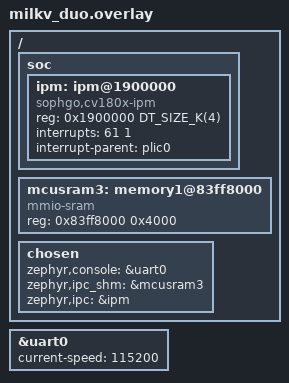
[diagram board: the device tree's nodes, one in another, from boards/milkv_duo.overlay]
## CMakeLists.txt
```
cmake_minimum_required(VERSION 3.20.0)
# Copyright (c) 2020 STMicroelectronics
#
# SPDX-License-Identifier: Apache-2.0
#

find_package(Zephyr REQUIRED HINTS $ENV{ZEPHYR_BASE})

project(openamp_tf)

# METAL_MAX_DEVICE_REGIONS is used to give the number of memory regions shared
# between processors. By default only one region is defined for the vrings
# and rpmsg buffers. The METAL_MAX_DEVICE_REGIONS has to be redefined to add a
# second region for the resource table.
zephyr_compile_definitions(METAL_MAX_DEVICE_REGIONS=2)

# These samples use local static initialization. Since Zephyr doesn't support the
# C++ ABI for thread-safe initialization of local statics and the constructors don't
# appear to require thread safety, we turn it off in the C++ compiler.
set(NO_THREADSAFE_STATICS $<TARGET_PROPERTY:compiler-cpp,no_threadsafe_statics>)
zephyr_compile_options($<$<COMPILE_LANGUAGE:CXX>:${NO_THREADSAFE_STATICS}>)

zephyr_linker_sources(SECTIONS src/resource_table.ld)

target_include_directories(app PRIVATE ${LIBMETAL_INCLUDE_DIR} ${OPENAMP_INCLUDE_DIR} ${PLATFORM_DIR})

list(APPEND CMAKE_MODULE_PATH ${ZEPHYR_BASE}/modules/nanopb)
include(nanopb)
zephyr_nanopb_sources(app src/message.proto)

file(GLOB app_sources src/*)
target_sources(app PRIVATE ${app_sources})
```

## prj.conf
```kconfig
# GENERAL ----------------
CONFIG_CONSOLE=y
CONFIG_UART_CONSOLE=y
CONFIG_STDOUT_CONSOLE=y
CONFIG_NANOPB=y
# CONFIG_TIMING_FUNCTIONS=y

# CONFIG_THREAD_ANALYZER=y
# CONFIG_THREAD_ANALYZER_USE_PRINTK=y
# CONFIG_THREAD_ANALYZER_AUTO=y
# CONFIG_THREAD_ANALYZER_AUTO_INTERVAL=5
# CONFIG_THREAD_NAME=y
# CONFIG_THREAD_RUNTIME_STATS=y

# OPENAMP ----------------
CONFIG_IPM=y
CONFIG_SOPHGO_CV180X_IPM=y
CONFIG_MAIN_STACK_SIZE=1024
CONFIG_HEAP_MEM_POOL_SIZE=1024
CONFIG_OPENAMP=y
CONFIG_OPENAMP_RSC_TABLE=y
CONFIG_OPENAMP_MASTER=n

# depends on size of RPMSG_BUFFER_SIZE declared in linux (driver/rpmsg/virtio_rpmsg_bus.c) and the reserved memory in devicetree
# ex: if reserved memory of each vring is 8kB and RPMSG_BUFFER_SIZE is 4kB, then CONFIG_OPENAMP_RSC_TABLE_NUM_RPMSG_BUFF=2
# RPMSG_BUFFER_SIZE = 4096 -> 	CONFIG_OPENAMP_RSC_TABLE_NUM_RPMSG_BUFF=2  	(max)
# RPMSG_BUFFER_SIZE = 2048 ->  	CONFIG_OPENAMP_RSC_TABLE_NUM_RPMSG_BUFF=4 	(max)
# RPMSG_BUFFER_SIZE = 512 ->  	CONFIG_OPENAMP_RSC_TABLE_NUM_RPMSG_BUFF=15 	(max)
CONFIG_OPENAMP_RSC_TABLE_NUM_RPMSG_BUFF=4

# TENSORFLOW LITE MICRO ----------------
CONFIG_CPP=y
CONFIG_STD_CPP17=y
CONFIG_TENSORFLOW_LITE_MICRO=y
CONFIG_MAIN_STACK_SIZE=2048
CONFIG_REQUIRES_FLOAT_PRINTF=y
```

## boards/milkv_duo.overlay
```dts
/ {
	#address-cells = <1>;
	#size-cells = <1>;
	
	soc {
		ipm:ipm@1900000 {
			compatible = "sophgo,cv180x-ipm";
			reg = <0x1900000 DT_SIZE_K(4)>;
			interrupts = <61 1>;
			interrupt-parent = <&plic0>;
			status = "disabled";
		};
	};

	// location of vdev0buffer in linux dts
	mcusram3: memory1@83ff8000 {
		compatible = "mmio-sram";
		reg = <0x83ff8000 0x4000>;
	};

	chosen {
		zephyr,console = &uart0;
		zephyr,ipc_shm = &mcusram3;
		zephyr,ipc = &ipm;
    };
};

&uart0 {
	status = "okay";
	current-speed = <115200>;
};

&ipm {
	status = "okay";
};
```

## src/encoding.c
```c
#include "encoding.h"
#include "src/message.pb.h"
#include <zephyr/kernel.h>

Board_Mark get_mark(char mark)
{
	switch (mark) {
	case 'X':
		return Board_Mark_MARK_X;
	case 'O':
		return Board_Mark_MARK_O;
	default:
		return Board_Mark_MARK_EMPTY;
	}
}

char get_mark_char(Board_Mark mark)
{
	switch (mark) {
	case Board_Mark_MARK_X:
		return 'X';
	case Board_Mark_MARK_O:
		return 'O';
	default:
		return ' ';
	}
}

int encode_board(char board[3][3], uint8_t *buffer, size_t buffer_size)
{
	Board message = Board_init_zero;

	for (int i = 0; i < 3; i++) {
		for (int j = 0; j < 3; j++) {
			message.rows[i].marks[j] = get_mark(board[i][j]);
		}
		message.rows[i].marks_count = 3;
	}
	message.rows_count = 3;

	// create stream that will write to our buffer
	pb_ostream_t stream = pb_ostream_from_buffer(buffer, buffer_size);

	// Encode the message
	bool status = pb_encode(&stream, Board_fields, &message);
	size_t message_length = stream.bytes_written;

	if (!status) {
		printk("Encoding failed: %s\n", PB_GET_ERROR(&stream));
		return ERROR;
	}

	return message_length;
}

int decode_board(char board[3][3], uint8_t *buffer, size_t message_length)
{
	/* Initialize the message structure to zero */
	Board message = Board_init_zero;

	/* Create a stream that reads from the buffer */
	pb_istream_t stream = pb_istream_from_buffer(buffer, message_length);

	/* Decode the message */
	int status = pb_decode(&stream, Board_fields, &message);

	/* Check for decoding errors */
	if (!status) {
		printk("Decoding failed: %s\n", PB_GET_ERROR(&stream));
		return ERROR;
	}

	for (int i = 0; i < 3; i++) {
		for (int j = 0; j < 3; j++) {
			board[i][j] = get_mark_char(message.rows[i].marks[j]);
		}
	}

	return SUCCESS;
}
```

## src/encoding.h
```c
#ifndef ENCODING_H
#define ENCODING_H

#include <pb_encode.h>
#include <pb_decode.h>

#define ERROR   -1
#define SUCCESS 0

int encode_board(char board[3][3], uint8_t *buffer, size_t buffer_size);
int decode_board(char board[3][3], uint8_t *buffer, size_t buffer_size);

#endif // !ENCODING_H
```

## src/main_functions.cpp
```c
/*
 * Copyright 2020 The TensorFlow Authors. All Rights Reserved.
 *
 * Licensed under the Apache License, Version 2.0 (the "License");
 * you may not use this file except in compliance with the License.
 * You may obtain a copy of the License at
 *
 *     http://www.apache.org/licenses/LICENSE-2.0
 *
 * Unless required by applicable law or agreed to in writing, software
 * distributed under the License is distributed on an "AS IS" BASIS,
 * WITHOUT WARRANTIES OR CONDITIONS OF ANY KIND, either express or implied.
 * See the License for the specific language governing permissions and
 * limitations under the License.
 */

#include "main_functions.h"

#include <tensorflow/lite/micro/micro_mutable_op_resolver.h>
#include "constants.h"
#include "model.hpp"
#include "output_handler.hpp"
#include <tensorflow/lite/micro/micro_log.h>
#include <tensorflow/lite/micro/micro_interpreter.h>
#include <tensorflow/lite/micro/system_setup.h>
#include <tensorflow/lite/schema/schema_generated.h>

/* Globals, used for compatibility with Arduino-style sketches. */
namespace
{
const tflite::Model *model = nullptr;
tflite::MicroInterpreter *interpreter = nullptr;
TfLiteTensor *input = nullptr;
TfLiteTensor *output = nullptr;
int inference_count = 0;

constexpr int kTensorArenaSize = 2000;
uint8_t tensor_arena[kTensorArenaSize];
} /* namespace */

/* The name of this function is important for Arduino compatibility. */
void setup(void)
{
	/* Map the model into a usable data structure. This doesn't involve any
	 * copying or parsing, it's a very lightweight operation.
	 */
	model = tflite::GetModel(g_model);
	if (model->version() != TFLITE_SCHEMA_VERSION) {
		MicroPrintf("Model provided is schema version %d not equal "
			    "to supported version %d.",
			    model->version(), TFLITE_SCHEMA_VERSION);
		return;
	}

	/* This pulls in the operation implementations we need.
	 * NOLINTNEXTLINE(runtime-global-variables)
	 */
	static tflite::MicroMutableOpResolver<1> resolver;
	resolver.AddFullyConnected();

	/* Build an interpreter to run the model with. */
	static tflite::MicroInterpreter static_interpreter(model, resolver, tensor_arena,
							   kTensorArenaSize);
	interpreter = &static_interpreter;

	/* Allocate memory from the tensor_arena for the model's tensors. */
	TfLiteStatus allocate_status = interpreter->AllocateTensors();
	if (allocate_status != kTfLiteOk) {
		MicroPrintf("AllocateTensors() failed");
		return;
	}

	/* Obtain pointers to the model's input and output tensors. */
	input = interpreter->input(0);
	output = interpreter->output(0);

	/* Keep track of how many inferences we have performed. */
	inference_count = 0;
}

/* The name of this function is important for Arduino compatibility. */
void loop(void)
{
	/* Calculate an x value to feed into the model. We compare the current
	 * inference_count to the number of inferences per cycle to determine
	 * our position within the range of possible x values the model was
	 * trained on, and use this to calculate a value.
	 */
	float position =
		static_cast<float>(inference_count) / static_cast<float>(kInferencesPerCycle);
	float x = position * kXrange;

	float y = infer(x);

	/* Output the results. A custom HandleOutput function can be implemented
	 * for each supported hardware target.
	 */
	HandleOutput(x, y);

	/* Increment the inference_counter, and reset it if we have reached
	 * the total number per cycle
	 */
	inference_count += 1;
	if (inference_count >= kInferencesPerCycle) {
		inference_count = 0;
	}
}

float infer(float x)
{
	/* Quantize the input from floating-point to integer */
	int8_t x_quantized = x / input->params.scale + input->params.zero_point;
	/* Place the quantized input in the model's input tensor */
	input->data.int8[0] = x_quantized;

	/* Run inference, and report any error */
	TfLiteStatus invoke_status = interpreter->Invoke();
	if (invoke_status != kTfLiteOk) {
		MicroPrintf("Invoke failed on x: %f\n", static_cast<double>(x));
		return -1;
	}

	/* Obtain the quantized output from model's output tensor */
	int8_t y_quantized = output->data.int8[0];
	/* Dequantize the output from integer to floating-point */
	float y = (y_quantized - output->params.zero_point) * output->params.scale;

	return y;
}
```

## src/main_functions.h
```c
/*
 * Copyright 2020 The TensorFlow Authors. All Rights Reserved.
 *
 * Licensed under the Apache License, Version 2.0 (the "License");
 * you may not use this file except in compliance with the License.
 * You may obtain a copy of the License at
 *
 *     http://www.apache.org/licenses/LICENSE-2.0
 *
 * Unless required by applicable law or agreed to in writing, software
 * distributed under the License is distributed on an "AS IS" BASIS,
 * WITHOUT WARRANTIES OR CONDITIONS OF ANY KIND, either express or implied.
 * See the License for the specific language governing permissions and
 * limitations under the License.
 */

#ifndef TENSORFLOW_LITE_MICRO_EXAMPLES_HELLO_WORLD_MAIN_FUNCTIONS_H_
#define TENSORFLOW_LITE_MICRO_EXAMPLES_HELLO_WORLD_MAIN_FUNCTIONS_H_

/* Expose a C friendly interface for main functions. */
#ifdef __cplusplus
extern "C" {
#endif

/* Initializes all data needed for the example. The name is important, and needs
 * to be setup() for Arduino compatibility.
 */
void setup(void);

/* Runs one iteration of data gathering and inference. This should be called
 * repeatedly from the application code. The name needs to be loop() for Arduino
 * compatibility.
 */
void loop(void);

/* Run inference on the data provided.
 */
float infer(float x);

#ifdef __cplusplus
}
#endif

#endif /* TENSORFLOW_LITE_MICRO_EXAMPLES_HELLO_WORLD_MAIN_FUNCTIONS_H_ */
```

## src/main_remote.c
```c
/*
 * Copyright (c) 2020, STMICROELECTRONICS
 *
 * SPDX-License-Identifier: Apache-2.0
 */

#include "openamp/rpmsg.h"
#include "main_functions.h"
#include "tictactoe.h"
#include "encoding.h"

#include <zephyr/sys/printk.h>
#include <zephyr/kernel.h>
#include <zephyr/device.h>
#include <stdint.h>
#include <string.h>
#include <stdio.h>
#include <stdlib.h>
#include <string.h>

#include <zephyr/drivers/ipm.h>

#include <openamp/open_amp.h>
#include <metal/device.h>
#include <resource_table.h>

#include <zephyr/logging/log.h>

LOG_MODULE_REGISTER(openamp_rsc_table, LOG_LEVEL_INF);

#define SHM_DEVICE_NAME "shm"

#define MBOX_TX_CHAN 2
#define MBOX_RX_CHAN 3

#if !DT_HAS_CHOSEN(zephyr_ipc_shm)
#error "Sample requires definition of shared memory for rpmsg"
#endif

/* Constants derived from device tree */
#define SHM_NODE       DT_CHOSEN(zephyr_ipc_shm)
#define SHM_START_ADDR DT_REG_ADDR(SHM_NODE)
#define SHM_SIZE       DT_REG_SIZE(SHM_NODE)

static const struct device *const ipm_handle = DEVICE_DT_GET(DT_CHOSEN(zephyr_ipc));

static metal_phys_addr_t shm_physmap = SHM_START_ADDR;

struct metal_device shm_device = {.name = SHM_DEVICE_NAME,
				  .num_regions = 2,
				  .regions =
					  {
						  {.virt = NULL}, /* shared memory */
						  {.virt = NULL}, /* rsc_table memory */
					  },
				  .node = {NULL},
				  .irq_num = 0,
				  .irq_info = NULL};

struct rpmsg_rcv_msg {
	void *data;
	size_t len;
};

static struct metal_io_region *shm_io;
static struct rpmsg_virtio_shm_pool shpool;

static struct metal_io_region *rsc_io;
static struct rpmsg_virtio_device rvdev;

static void *rsc_table;
static struct rpmsg_device *rpdev;

static K_SEM_DEFINE(data_sem, 0, 1);

// app specific variables
#define APP_RPMSG_TASK_STACK_SIZE (2048)
static K_SEM_DEFINE(data_app_sem, 0, 1);
K_THREAD_STACK_DEFINE(thread_netlink_stack, APP_RPMSG_TASK_STACK_SIZE);

#define APP_TTT_TASK_STACK_SIZE (4096)
static K_SEM_DEFINE(data_ttt_sem, 0, 1);
K_THREAD_STACK_DEFINE(thread_ttt_stack, APP_TTT_TASK_STACK_SIZE);

#define APP_MNG_TASK_STACK_SIZE (1024)
K_THREAD_STACK_DEFINE(thread_mng_stack, APP_MNG_TASK_STACK_SIZE);

static void platform_ipm_callback(const struct device *dev, void *context, uint32_t id,
				  volatile void *data)
{
	LOG_DBG("msg received from mailbox chan %d\n", id);
	if (id == MBOX_RX_CHAN) {
		k_sem_give(&data_sem);
	}
}

static int rpmsg_recv_ttt_callback(struct rpmsg_endpoint *ept, void *data, size_t len, uint32_t src,
				   void *priv)
{
	struct rpmsg_rcv_msg *msg = priv;

	rpmsg_hold_rx_buffer(ept, data);
	msg->data = data;
	msg->len = len;
	k_sem_give(&data_ttt_sem);

	return RPMSG_SUCCESS;
}

static int rpmsg_recv_netlink_callback(struct rpmsg_endpoint *ept, void *data, size_t len,
				       uint32_t src, void *priv)
{
	struct rpmsg_rcv_msg *msg = priv;

	rpmsg_hold_rx_buffer(ept, data);
	msg->data = data;
	msg->len = len;
	k_sem_give(&data_app_sem);

	return RPMSG_SUCCESS;
}

static void receive_message(unsigned char **msg, unsigned int *len)
{
	int status = k_sem_take(&data_sem, K_FOREVER);

	if (status == 0) {
		rproc_virtio_notified(rvdev.vdev, VRING1_ID);
	}
}

static void new_service_cb(struct rpmsg_device *rdev, const char *name, uint32_t src)
{
	LOG_ERR("%s: unexpected ns service receive for name %s\n", __func__, name);
}

int mailbox_notify(void *priv, uint32_t id)
{
	ARG_UNUSED(priv);

	if (id == 0) {
		LOG_DBG("sending kick to mailbox chan %d\n", MBOX_TX_CHAN);
		ipm_send(ipm_handle, 0, MBOX_TX_CHAN, NULL, 0);
	}

	return 0;
}

unsigned long phys_to_offset(struct metal_io_region *io, metal_phys_addr_t phys)
{
	return (unsigned long)phys - (unsigned long)io->virt;
}

int platform_init(void)
{
	void *rsc_tab_addr;
	int rsc_size;
	struct metal_device *device;
	struct metal_init_params metal_params = METAL_INIT_DEFAULTS;
	int status;

	const struct metal_io_ops nops = {
		.phys_to_offset = phys_to_offset,
	};

	status = metal_init(&metal_params);
	if (status) {
		LOG_DBG("metal_init: failed: %d\n", status);
		return -1;
	}

	status = metal_register_generic_device(&shm_device);
	if (status) {
		LOG_DBG("Couldn't register shared memory: %d\n", status);
		return -1;
	}

	status = metal_device_open("generic", SHM_DEVICE_NAME, &device);
	if (status) {
		LOG_DBG("metal_device_open failed: %d\n", status);
		return -1;
	}

	/* declare shared memory region */
	metal_io_init(&device->regions[0], (void *)SHM_START_ADDR, &shm_physmap, SHM_SIZE, -1, 0,
		      &nops);

	shm_io = metal_device_io_region(device, 0);
	if (!shm_io) {
		LOG_DBG("Failed to get shm_io region\n");
		return -1;
	}

	/* declare resource table region */
	rsc_table_get((struct fw_resource_table **)&rsc_tab_addr, &rsc_size);
	rsc_table = (struct st_resource_table *)rsc_tab_addr;

	metal_io_init(&device->regions[1], rsc_table, (metal_phys_addr_t *)rsc_table, rsc_size, -1,
		      0, NULL);

	rsc_io = metal_device_io_region(device, 1);
	if (!rsc_io) {
		LOG_DBG("Failed to get rsc_io region\n");
		return -1;
	}

	/* setup IPM */
	if (!device_is_ready(ipm_handle)) {
		LOG_DBG("IPM device is not ready\n");
		return -1;
	}

	ipm_register_callback(ipm_handle, platform_ipm_callback, NULL);

	status = ipm_set_enabled(ipm_handle, 1);
	if (status) {
		LOG_DBG("ipm_set_enabled failed\n");
		return -1;
	}

	return 0;
}

static void cleanup_system(void)
{
	ipm_set_enabled(ipm_handle, 0);
	rpmsg_deinit_vdev(&rvdev);
	metal_finish();
}

struct rpmsg_device *platform_create_rpmsg_vdev(unsigned int vdev_index, unsigned int role,
						void (*rst_cb)(struct virtio_device *vdev),
						rpmsg_ns_bind_cb ns_cb)
{
	struct fw_rsc_vdev_vring *vring_rsc;
	struct virtio_device *vdev;
	int ret;

	vdev = rproc_virtio_create_vdev(VIRTIO_DEV_DEVICE, VDEV_ID, rsc_table_to_vdev(rsc_table),
					rsc_io, NULL, mailbox_notify, NULL);

	if (!vdev) {
		LOG_DBG("failed to create vdev\r\n");
		return NULL;
	}

	/* wait master rpmsg init completion */
	rproc_virtio_wait_remote_ready(vdev);

	vring_rsc = rsc_table_get_vring0(rsc_table);
	ret = rproc_virtio_init_vring(vdev, 0, vring_rsc->notifyid,
				      (void *)(uintptr_t)(vring_rsc->da), rsc_io, vring_rsc->num,
				      vring_rsc->align);
	if (ret) {
		LOG_DBG("failed to init vring 0\r\n");
		goto failed;
	}

	vring_rsc = rsc_table_get_vring1(rsc_table);
	ret = rproc_virtio_init_vring(vdev, 1, vring_rsc->notifyid,
				      (void *)(uintptr_t)vring_rsc->da, rsc_io, vring_rsc->num,
				      vring_rsc->align);
	if (ret) {
		LOG_DBG("failed to init vring 1\r\n");
		goto failed;
	}

	rpmsg_virtio_init_shm_pool(&shpool, NULL, SHM_SIZE);
	ret = rpmsg_init_vdev(&rvdev, vdev, ns_cb, shm_io, &shpool);

	if (ret) {
		LOG_DBG("failed rpmsg_init_vdev\r\n");
		goto failed;
	}

	return rpmsg_virtio_get_rpmsg_device(&rvdev);

failed:
	rproc_virtio_remove_vdev(vdev);

	return NULL;
}

void ttt(void *arg1, void *arg2, void *arg3)
{
	ARG_UNUSED(arg1);
	ARG_UNUSED(arg2);
	ARG_UNUSED(arg3);

	static struct rpmsg_endpoint ept;
	static struct rpmsg_rcv_msg msg;

	int ret = 0;

	k_sem_take(&data_ttt_sem, K_FOREVER);

	printk("\r\nOpenAMP[remote] rpmsg-ttt tictactoe player started\r\n");

	ept.priv = &msg;
	ret = rpmsg_create_ept(&ept, rpdev, "rpmsg-ttt", RPMSG_ADDR_ANY, RPMSG_ADDR_ANY,
			       rpmsg_recv_ttt_callback, NULL);

	char board[3][3] = {{' '}, {' '}, {' '}};

	while (ept.addr != RPMSG_ADDR_ANY) {
		k_sem_take(&data_ttt_sem, K_FOREVER);

		ret = decode_board(board, (uint8_t *)msg.data, msg.len);
		if (ret < 0) {
			printk("Decoding failed\n");
			continue;
		}

		// determine the best move
		struct action best_move;
		minimax(board, &best_move);

		if (best_move.row == -1) {
			// game over
			rpmsg_send(&ept, msg.data, msg.len);
			continue;
		}

		// make move
		board[best_move.row][best_move.col] = player(board);

		draw(board);

		// encode board
		ret = encode_board(board, (uint8_t *)msg.data, msg.len);

		if (ret < 0) {
			printk("Encoding failed\n");
			continue;
		}

		rpmsg_send(&ept, msg.data, ret);

		msg.len = 0;
		rpmsg_release_rx_buffer(&ept, msg.data);
	}

	rpmsg_destroy_ept(&ept);
}

void app(void *arg1, void *arg2, void *arg3)
{
	ARG_UNUSED(arg1);
	ARG_UNUSED(arg2);
	ARG_UNUSED(arg3);

	static struct rpmsg_endpoint ept;
	static struct rpmsg_rcv_msg msg;

	int ret = 0;

	// initialize tensorflow
	setup();

	k_sem_take(&data_app_sem, K_FOREVER);

	printk("\r\nOpenAMP[remote] rpmsg-tflite tensorflow sine predictor started\r\n");

	ept.priv = &msg;
	ret = rpmsg_create_ept(&ept, rpdev, "rpmsg-tflite", RPMSG_ADDR_ANY, RPMSG_ADDR_ANY,
			       rpmsg_recv_netlink_callback, NULL);

	while (ept.addr != RPMSG_ADDR_ANY) {
		k_sem_take(&data_app_sem, K_FOREVER);

		if (msg.len) {
			// process app data
			float *input = (float *)msg.data;
			for (int i = 0; i < msg.len / sizeof(float); i++) {
				float x = input[i];
				float y = infer(x);
				input[i] = y;
			}

			rpmsg_send(&ept, msg.data, msg.len);
		}

		msg.len = 0;
		rpmsg_release_rx_buffer(&ept, msg.data);
	}

	rpmsg_destroy_ept(&ept);
}

void rpmsg_mng_task(void *arg1, void *arg2, void *arg3)
{
	ARG_UNUSED(arg1);
	ARG_UNUSED(arg2);
	ARG_UNUSED(arg3);

	unsigned char *msg;
	unsigned int len;
	int ret = 0;

	printk("\r\nOpenAMP[remote] application started\r\n");

	/* Initialize platform */
	ret = platform_init();
	if (ret) {
		LOG_ERR("Failed to initialize platform\n");
		ret = -1;
		goto task_end;
	}

	// Create rpmsg vdev - Only one shared channel, different services are provided through
	// different endpoints
	rpdev = platform_create_rpmsg_vdev(0, VIRTIO_DEV_DEVICE, NULL, new_service_cb);
	if (!rpdev) {
		LOG_ERR("Failed to create rpmsg virtio device\n");
		ret = -1;
		goto task_end;
	}

	printk("RPMSG tx buffer size: %d\n", rpmsg_virtio_get_tx_buffer_size(rpdev));

	/* start the rpmsg clients */
	k_sem_give(&data_app_sem);
	k_sem_give(&data_ttt_sem);

	while (1) {
		receive_message(&msg, &len);
	}

task_end:
	cleanup_system();

	printk("OpenAMP demo ended\n");
}

int main(void)
{
	printk("Starting application threads!\n");

	static struct k_thread thread_app_data;
	static struct k_thread thread_mng_data;
	static struct k_thread thread_ttt_data;

	k_tid_t mng =
		k_thread_create(&thread_mng_data, thread_mng_stack, APP_MNG_TASK_STACK_SIZE,
				rpmsg_mng_task, NULL, NULL, NULL, K_PRIO_COOP(8), 0, K_NO_WAIT);

	k_tid_t app_thread =
		k_thread_create(&thread_app_data, thread_netlink_stack, APP_RPMSG_TASK_STACK_SIZE,
				app, NULL, NULL, NULL, K_PRIO_COOP(7), 0, K_NO_WAIT);

	k_tid_t ttt_thread =
		k_thread_create(&thread_ttt_data, thread_ttt_stack, APP_TTT_TASK_STACK_SIZE, ttt,
				NULL, NULL, NULL, K_PRIO_COOP(7), 0, K_NO_WAIT);

	k_thread_name_set(mng, "manager");
	k_thread_name_set(app_thread, "sine_predictor");
	k_thread_name_set(ttt_thread, "ttt");

	return 0;
}
```

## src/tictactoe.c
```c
#include "tictactoe.h"
#include <stdio.h>
#include <limits.h>

#define X     'X'
#define O     'O'
#define EMPTY ' '

/**
 * @brief Initialize the board to the initial state
 */
void initial_state(char board[3][3])
{
	for (int i = 0; i < 3; i++) {
		for (int j = 0; j < 3; j++) {
			board[i][j] = EMPTY;
		}
	}
}

/**
 * @brief Determine the current player
 * @param board The current board
 * @return char The current player
 */
char player(char board[3][3])
{
	int x_count = 0, o_count = 0;
	for (int i = 0; i < 3; i++) {
		for (int j = 0; j < 3; j++) {
			if (board[i][j] == X) {
				x_count++;
			} else if (board[i][j] == O) {
				o_count++;
			}
		}
	}
	return (x_count > o_count) ? O : X;
}

/**
 * @brief Determine the available actions
 * @param board The current board
 * @param action_list The list of available actions
 * @return int The number of available actions
 */
int actions(char board[3][3], struct action action_list[9])
{
	int count = 0;
	for (int i = 0; i < 3; i++) {
		for (int j = 0; j < 3; j++) {
			if (board[i][j] == EMPTY) {
				action_list[count].row = i;
				action_list[count].col = j;
				count++;
			}
		}
	}
	return count;
}

/**
 * @brief Apply a move and return a new board
 * @param new_board The new board
 * @param board The current board
 * @param action The action to apply
 */
void result(char new_board[3][3], char board[3][3], struct action action)
{
	for (int k = 0; k < 3; k++) {
		for (int l = 0; l < 3; l++) {
			new_board[k][l] = board[k][l];
		}
	}
	new_board[action.row][action.col] = player(board);
}

/**
 * @brief Check for a winner
 * @param board The current board
 * @return char The winner
 */
char winner(char board[3][3])
{
	for (int i = 0; i < 3; i++) {
		if (board[i][0] == board[i][1] && board[i][0] == board[i][2] &&
		    board[i][0] != EMPTY) {
			return board[i][0];
		}
		if (board[0][i] == board[1][i] && board[0][i] == board[2][i] &&
		    board[0][i] != EMPTY) {
			return board[0][i];
		}
	}
	if (board[0][0] == board[1][1] && board[0][0] == board[2][2] && board[0][0] != EMPTY) {
		return board[0][0];
	}
	if (board[0][2] == board[1][1] && board[0][2] == board[2][0] && board[0][2] != EMPTY) {
		return board[0][2];
	}
	return EMPTY;
}

/**
 * @brief Check if the game is over
 * @param board The current board
 * @return int 1 if the game is over, 0 otherwise
 */
int terminal(char board[3][3])
{
	if (winner(board) != EMPTY) {
		return 1;
	}
	for (int i = 0; i < 3; i++) {
		for (int j = 0; j < 3; j++) {
			if (board[i][j] == EMPTY) {
				return 0;
			}
		}
	}
	return 1;
}

/**
 * @brief Calculate the utility of the board
 * @param board The current board
 * @return int The utility of the board
 */
int utility(char board[3][3])
{
	char win = winner(board);
	if (win == X) {
		return 1;
	} else if (win == O) {
		return -1;
	} else {
		return 0;
	}
}

// Maximize function
int Max_Value(char board[3][3]);

// Minimize function
int Min_Value(char board[3][3])
{
	if (terminal(board)) {
		return utility(board);
	}

	int v = INT_MAX;
	struct action action_list[9];
	int actions_count = actions(board, action_list);

	for (int i = 0; i < actions_count; i++) {
		char new_board[3][3];
		result(new_board, board, action_list[i]);
		int max_val = Max_Value(new_board);
		if (max_val < v) {
			v = max_val;
		}
	}
	return v;
}

// Maximize function
int Max_Value(char board[3][3])
{
	if (terminal(board)) {
		return utility(board);
	}

	int v = INT_MIN;
	struct action action_list[9];
	int actions_count = actions(board, action_list);

	for (int i = 0; i < actions_count; i++) {
		char new_board[3][3];
		result(new_board, board, action_list[i]);
		int min_val = Min_Value(new_board);
		if (min_val > v) {
			v = min_val;
		}
	}
	return v;
}

/**
 * @brief Minimax algorithm
 * @param board The current board
 * @param best_move The best move
 */
void minimax(char board[3][3], struct action *best_move)
{
	if (terminal(board)) {
		best_move->row = -1;
		best_move->col = -1;
		return;
	}

	int best_val;
	if (player(board) == X) {
		best_val = INT_MIN;
	} else {
		best_val = INT_MAX;
	}

	struct action action_list[9];
	int actions_count = actions(board, action_list);

	for (int i = 0; i < actions_count; i++) {
		char new_board[3][3];
		result(new_board, board, action_list[i]);

		int current_val;
		if (player(board) == X) {
			current_val = Min_Value(new_board);
			if (current_val > best_val) {
				best_val = current_val;
				best_move->row = action_list[i].row;
				best_move->col = action_list[i].col;
			}
		} else {
			current_val = Max_Value(new_board);
			if (current_val < best_val) {
				best_val = current_val;
				best_move->row = action_list[i].row;
				best_move->col = action_list[i].col;
			}
		}
	}
}

/**
 * @brief Draw the board
 * @param board The current board
 */
void draw(char board[3][3])
{
	// printf("\033[H\033[J"); // clear screen
	printf("\t0\t1\t2\n\n");
	for (int i = 0; i < 3; i++) {
		printf("%d", i);
		for (int j = 0; j < 3; j++) {
			printf("\t%c", board[i][j]);
		}
		printf("\n\n");
	}
}

char BOARD[3][3];
int user_turn;
char play_marker;

static void setup()
{
	initial_state(BOARD);
	printf("Do you want to play first? (1 for yes, 0 for no): ");
	scanf("%d", &user_turn);
	user_turn = user_turn ? 1 : 0;
	play_marker = user_turn ? X : O;
}

static void loop()
{
	struct action best_move;
	struct action user_move;

	while (!terminal(BOARD)) {
		draw(BOARD);
		printf("You are %c\n", play_marker);

		if (user_turn) {
			printf("Enter your move (row column): ");
			while (1) {
				scanf("%d %d", &user_move.row, &user_move.col);
				if (user_move.row < 0 || user_move.row > 2 || user_move.col < 0 ||
				    user_move.col > 2) {
					printf("Invalid move, try again: ");
					continue;
				}
				if (BOARD[user_move.row][user_move.col] == EMPTY) {
					break;
				}
				printf("Invalid move, try again: ");
			}
			BOARD[user_move.row][user_move.col] = player(BOARD);
			user_turn = 0;
		} else {
			minimax(BOARD, &best_move);
			if (best_move.row == -1) {
				break;
			}
			BOARD[best_move.row][best_move.col] = player(BOARD);
			user_turn = 1;
		}
	}

	draw(BOARD);
	printf("You are %c\n", play_marker);
	if (winner(BOARD) == X) {
		printf("X wins!\n");
	} else if (winner(BOARD) == O) {
		printf("O wins!\n");
	} else {
		printf("It's a draw!\n");
	}
}
```

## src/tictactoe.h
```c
#ifndef TICTACTOE_H
#define TICTACTOE_H

struct action {
	int row;
	int col;
};

/**
 * @brief Minimax algorithm
 * @param board The current board
 * @param best_move The best move
 */
void minimax(char board[3][3], struct action *best_move);

/**
 * @brief Determine the current player
 * @param board The current board
 * @return char The current player
 */
char player(char board[3][3]);

void draw(char board[3][3]);

#endif // !TICTACTOE_H
```
